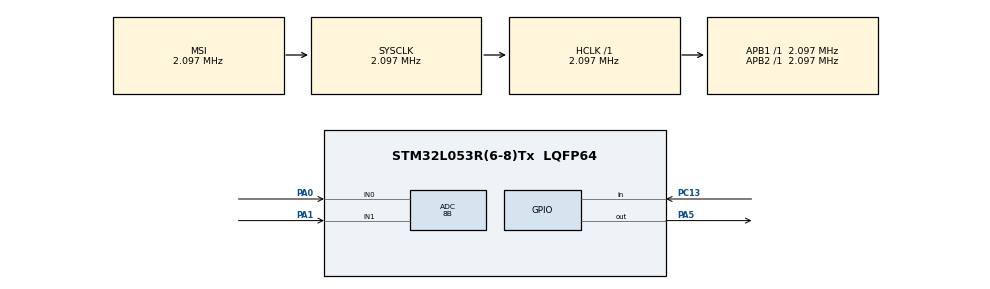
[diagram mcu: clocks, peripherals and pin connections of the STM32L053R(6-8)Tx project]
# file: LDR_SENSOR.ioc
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ADC.Resolution=ADC_RESOLUTION_8B
ADC.SamplingTime=ADC_SAMPLETIME_39CYCLES_5
Mcu.Family=STM32L0
Mcu.Name=STM32L053R(6-8)Tx
Mcu.Package=LQFP64
PA0.Mode=IN0
PA0.Signal=ADC_IN0
PA1.Mode=IN1
PA1.Signal=ADC_IN1
PA5.Signal=GPIO_Output
PC13.Signal=GPIO_Input
ProjectManager.HeapSize=0x200
ProjectManager.StackSize=0x400
ProjectManager.TargetToolchain=STM32CubeIDE
RCC.AHBFreq_Value=2097000
RCC.APB1Freq_Value=2097000
RCC.APB1TimFreq_Value=2097000
RCC.APB2Freq_Value=2097000
RCC.APB2TimFreq_Value=2097000
RCC.HSE_VALUE=8000000
RCC.HSI16_VALUE=16000000
RCC.HSI48_VALUE=48000000
RCC.HSI_VALUE=16000000
RCC.LSE_VALUE=32768
RCC.MSI_VALUE=2097000
RCC.SYSCLKFreq_VALUE=2097000
RCC.VCOOutputFreq_Value=48000000
board=NUCLEO-L053R8

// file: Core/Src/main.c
/* USER CODE BEGIN Header */
/**
  ******************************************************************************
  * @file           : main.c
  * @brief          : Main program body
  ******************************************************************************
  * @attention
  *
  * Copyright (c) 2023 STMicroelectronics.
  * All rights reserved.
  *
  * This software is licensed under terms that can be found in the LICENSE file
  * in the root directory of this software component.
  * If no LICENSE file comes with this software, it is provided AS-IS.
  *
  ******************************************************************************
  */
/* USER CODE END Header */
#include "main.h"
#include <stdio.h>

ADC_HandleTypeDef hadc;

void SystemClock_Config(void);
static void MX_GPIO_Init(void);
static void MX_ADC_Init(void);

uint32_t adcVal0;
uint32_t adcVal1;
uint32_t DOval;
ADC_ChannelConfTypeDef sConfig;

int main(void)
{

  /* MCU Configuration--------------------------------------------------------*/

  /* Reset of all peripherals, Initializes the Flash interface and the Systick. */
  HAL_Init();

  /* Configure the system clock */
  SystemClock_Config();

  /* Initialize all configured peripherals */
  MX_GPIO_Init();
  MX_ADC_Init();

  /* Infinite loop */
  /* USER CODE BEGIN WHILE */
  while (1)
  {
      if (GPIOA->IDR & GPIO_IDR_ID5) {
          DOval = 1; // D13 is high
      } else {
          DOval = 0; // D13 is low
      }
    /* USER CODE END WHILE */

    /* USER CODE BEGIN 3 */
	  sConfig.Channel = ADC_CHANNEL_0;
	  HAL_ADC_ConfigChannel(&hadc, &sConfig);
	  HAL_ADC_Start(&hadc);
	  if(HAL_ADC_PollForConversion(&hadc,5) == HAL_OK)
	  {
		  adcVal0 = HAL_ADC_GetValue(&hadc);
	  }
/*	  sConfig.Channel = ADC_CHANNEL_1;
	  HAL_ADC_ConfigChannel(&hadc, &sConfig);
	  HAL_ADC_Start(&hadc);
	  if(HAL_ADC_PollForConversion(&hadc,5) == HAL_OK)
	  {
		  adcVal0 = HAL_ADC_GetValue(&hadc);
	  }*/
	  printf("ADC = %ld\n",adcVal0);
	  printf("Digital = %ld\n",DOval);

	  HAL_Delay(50);
  }
  /* USER CODE END 3 */
}

void SystemClock_Config(void)
{
  RCC_OscInitTypeDef RCC_OscInitStruct = {0};
  RCC_ClkInitTypeDef RCC_ClkInitStruct = {0};

  /** Configure the main internal regulator output voltage
  */
  __HAL_PWR_VOLTAGESCALING_CONFIG(PWR_REGULATOR_VOLTAGE_SCALE1);

  /** Initializes the RCC Oscillators according to the specified parameters
  * in the RCC_OscInitTypeDef structure.
  */
  RCC_OscInitStruct.OscillatorType = RCC_OSCILLATORTYPE_MSI;
  RCC_OscInitStruct.MSIState = RCC_MSI_ON;
  RCC_OscInitStruct.MSICalibrationValue = 0;
  RCC_OscInitStruct.MSIClockRange = RCC_MSIRANGE_5;
  RCC_OscInitStruct.PLL.PLLState = RCC_PLL_NONE;
  if (HAL_RCC_OscConfig(&RCC_OscInitStruct) != HAL_OK)
  {
    Error_Handler();
  }

  /** Initializes the CPU, AHB and APB buses clocks
  */
  RCC_ClkInitStruct.ClockType = RCC_CLOCKTYPE_HCLK|RCC_CLOCKTYPE_SYSCLK
                              |RCC_CLOCKTYPE_PCLK1|RCC_CLOCKTYPE_PCLK2;
  RCC_ClkInitStruct.SYSCLKSource = RCC_SYSCLKSOURCE_MSI;
  RCC_ClkInitStruct.AHBCLKDivider = RCC_SYSCLK_DIV1;
  RCC_ClkInitStruct.APB1CLKDivider = RCC_HCLK_DIV1;
  RCC_ClkInitStruct.APB2CLKDivider = RCC_HCLK_DIV1;

  if (HAL_RCC_ClockConfig(&RCC_ClkInitStruct, FLASH_LATENCY_0) != HAL_OK)
  {
    Error_Handler();
  }
}

static void MX_ADC_Init(void)
{

 // ADC_ChannelConfTypeDef sConfig = {0};

  /** Configure the global features of the ADC (Clock, Resolution, Data Alignment and number of conversion)
  */
  hadc.Instance = ADC1;
  hadc.Init.OversamplingMode = DISABLE;
  hadc.Init.ClockPrescaler = ADC_CLOCK_SYNC_PCLK_DIV1;
  hadc.Init.Resolution = ADC_RESOLUTION_8B;
  hadc.Init.SamplingTime = ADC_SAMPLETIME_39CYCLES_5;
  hadc.Init.ScanConvMode = ADC_SCAN_DIRECTION_FORWARD;
  hadc.Init.DataAlign = ADC_DATAALIGN_RIGHT;
  hadc.Init.ContinuousConvMode = DISABLE;
  hadc.Init.DiscontinuousConvMode = DISABLE;
  hadc.Init.ExternalTrigConvEdge = ADC_EXTERNALTRIGCONVEDGE_NONE;
  hadc.Init.ExternalTrigConv = ADC_SOFTWARE_START;
  hadc.Init.DMAContinuousRequests = DISABLE;
  hadc.Init.EOCSelection = ADC_EOC_SINGLE_CONV;
  hadc.Init.Overrun = ADC_OVR_DATA_PRESERVED;
  hadc.Init.LowPowerAutoWait = DISABLE;
  hadc.Init.LowPowerFrequencyMode = ENABLE;
  hadc.Init.LowPowerAutoPowerOff = DISABLE;
  if (HAL_ADC_Init(&hadc) != HAL_OK)
  {
    Error_Handler();
  }

  /** Configure for the selected ADC regular channel to be converted.
  */
  sConfig.Channel = ADC_CHANNEL_0;
  sConfig.Rank = ADC_RANK_CHANNEL_NUMBER;
  if (HAL_ADC_ConfigChannel(&hadc, &sConfig) != HAL_OK)
  {
    Error_Handler();
  }

  /** Configure for the selected ADC regular channel to be converted.
  */
  sConfig.Channel = ADC_CHANNEL_1;
  if (HAL_ADC_ConfigChannel(&hadc, &sConfig) != HAL_OK)
  {
    Error_Handler();
  }

}

static void MX_GPIO_Init(void)
{
  GPIO_InitTypeDef GPIO_InitStruct = {0};

  /* GPIO Ports Clock Enable */
  __HAL_RCC_GPIOC_CLK_ENABLE();
  __HAL_RCC_GPIOA_CLK_ENABLE();

  /*Configure GPIO pin Output Level */
  HAL_GPIO_WritePin(GPIOA, GPIO_PIN_5, GPIO_PIN_RESET);

  /*Configure GPIO pin : PC13 */
  GPIO_InitStruct.Pin = GPIO_PIN_13;
  GPIO_InitStruct.Mode = GPIO_MODE_INPUT;
  GPIO_InitStruct.Pull = GPIO_NOPULL;
  HAL_GPIO_Init(GPIOC, &GPIO_InitStruct);

  /*Configure GPIO pin : PA5 */
  GPIO_InitStruct.Pin = GPIO_PIN_5;
  GPIO_InitStruct.Mode = GPIO_MODE_INPUT;
  GPIO_InitStruct.Pull = GPIO_NOPULL;
  GPIO_InitStruct.Speed = GPIO_SPEED_FREQ_LOW;
  HAL_GPIO_Init(GPIOA, &GPIO_InitStruct);

}

void Error_Handler(void)
{
  __disable_irq();
  while (1)
  {
  }
}
